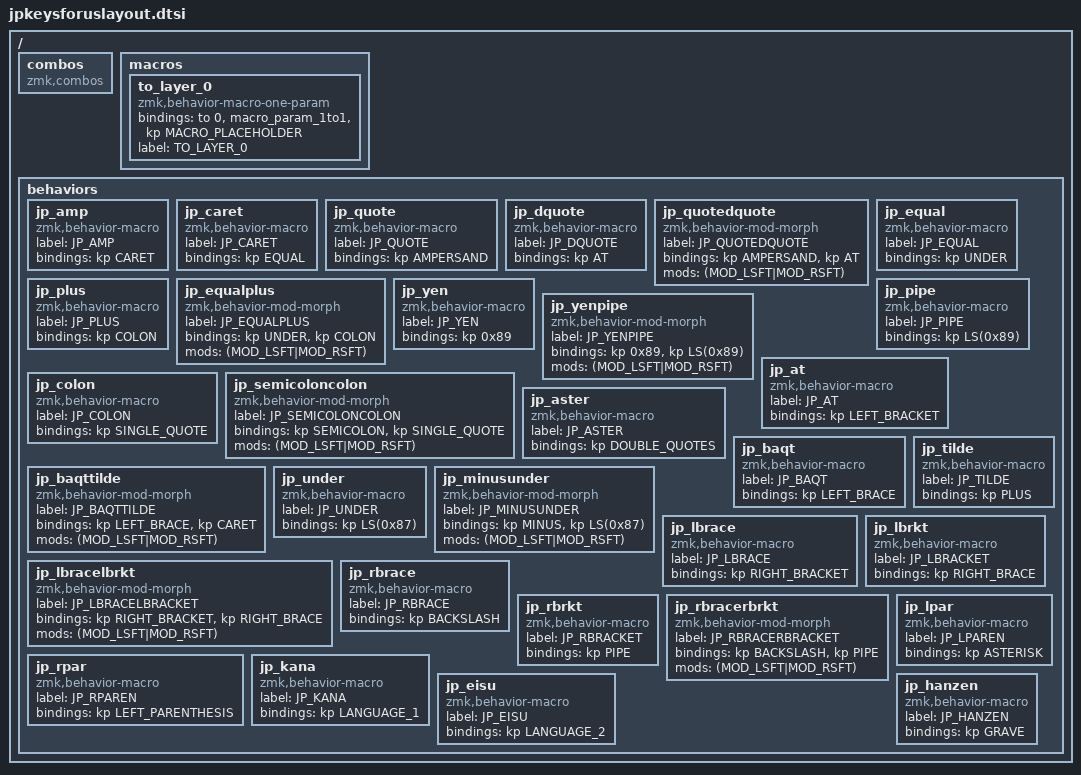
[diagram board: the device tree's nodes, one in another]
/*
 * Copyright (c) 2020 The ZMK Contributors
 *
 * SPDX-License-Identifier: MIT
 */

#include <behaviors.dtsi>
#include <dt-bindings/zmk/keys.h>

/ {
    combos { compatible = "zmk,combos"; };

    macros {
        to_layer_0: to_layer_0 {
            compatible = "zmk,behavior-macro-one-param";
            #binding-cells = <1>;
            bindings = <&to 0 &macro_param_1to1 &kp MACRO_PLACEHOLDER>;
            label = "TO_LAYER_0";
        };
    };

    behaviors {
        /* 日本語キーボード用マクロ定義 */

        jp_amp: jp_amp {
            compatible = "zmk,behavior-macro";
            #binding-cells = <0>;
            label = "JP_AMP";
            bindings = <&kp CARET>;
        };

        jp_caret: jp_caret {
            compatible = "zmk,behavior-macro";
            #binding-cells = <0>;
            label = "JP_CARET";
            bindings = <&kp EQUAL>;
        };

        jp_quote: jp_quote {
            compatible = "zmk,behavior-macro";
            #binding-cells = <0>;
            label = "JP_QUOTE";
            bindings = <&kp AMPERSAND>;
        };

        jp_dquote: jp_dquote {
            compatible = "zmk,behavior-macro";
            #binding-cells = <0>;
            label = "JP_DQUOTE";
            bindings = <&kp AT>;
        };

        jp_quotedquote: jp_quotedquote {
            compatible = "zmk,behavior-mod-morph";
            #binding-cells = <0>;
            label = "JP_QUOTEDQUOTE";
            bindings = <&kp AMPERSAND>, <&kp AT>;
            mods = <(MOD_LSFT|MOD_RSFT)>;
        };

        jp_equal: jp_equal {
            compatible = "zmk,behavior-macro";
            #binding-cells = <0>;
            label = "JP_EQUAL";
            bindings = <&kp UNDER>>;
        };

        jp_plus: jp_plus {
            compatible = "zmk,behavior-macro";
            #binding-cells = <0>;
            label = "JP_PLUS";
            bindings = <&kp COLON>;
        };

        jp_equalplus: jp_equalplus {
            compatible = "zmk,behavior-mod-morph";
            #binding-cells = <0>;
            label = "JP_EQUALPLUS";
            bindings = <&kp UNDER>, <&kp COLON>;
            mods = <(MOD_LSFT|MOD_RSFT)>;
        };

        jp_yen: jp_yen {
            compatible = "zmk,behavior-macro";
            #binding-cells = <0>;
            label = "JP_YEN";
            bindings = <&kp 0x89>;
        };

        jp_pipe: jp_pipe {
            compatible = "zmk,behavior-macro";
            #binding-cells = <0>;
            label = "JP_PIPE";
            bindings = <&kp LS(0x89)>;
        };

        jp_yenpipe: jp_yenpipe {
            compatible = "zmk,behavior-mod-morph";
            #binding-cells = <0>;
            label = "JP_YENPIPE";
            bindings = <&kp 0x89>, <&kp LS(0x89)>;
            mods = <(MOD_LSFT|MOD_RSFT)>;
        };

        jp_at: jp_at {
            compatible = "zmk,behavior-macro";
            #binding-cells = <0>;
            label = "JP_AT";
            bindings = <&kp LEFT_BRACKET>;
        };

        jp_colon: jp_colon {
            compatible = "zmk,behavior-macro";
            #binding-cells = <0>;
            label = "JP_COLON";
            bindings = <&kp SINGLE_QUOTE>;
        };

        jp_semicoloncolon: jp_semicoloncolon {
            compatible = "zmk,behavior-mod-morph";
            #binding-cells = <0>;
            label = "JP_SEMICOLONCOLON";
            bindings = <&kp SEMICOLON>,<&kp SINGLE_QUOTE>;
            mods = <(MOD_LSFT|MOD_RSFT)>;
        };

        jp_aster: jp_aster {
            compatible = "zmk,behavior-macro";
            #binding-cells = <0>;
            label = "JP_ASTER";
            bindings = <&kp DOUBLE_QUOTES>;
        };

        jp_baqt: jp_baqt {
            compatible = "zmk,behavior-macro";
            #binding-cells = <0>;
            label = "JP_BAQT";
            bindings = <&kp LEFT_BRACE>;
        };

        jp_tilde: jp_tilde {
            compatible = "zmk,behavior-macro";
            #binding-cells = <0>;
            label = "JP_TILDE";
            bindings = <&kp PLUS>;
        };

        jp_baqttilde: jp_baqttilde {
            compatible = "zmk,behavior-mod-morph";
            #binding-cells = <0>;
            label = "JP_BAQTTILDE";
            bindings = <&kp LEFT_BRACE>, <&kp CARET>;
            mods = <(MOD_LSFT|MOD_RSFT)>;
        };

        jp_under: jp_under {
            compatible = "zmk,behavior-macro";
            #binding-cells = <0>;
            label = "JP_UNDER";
            bindings = <&kp LS(0x87)>;
        };

        jp_minusunder: jp_minusunder {
            compatible = "zmk,behavior-mod-morph";
            #binding-cells = <0>;
            label = "JP_MINUSUNDER";
            bindings = <&kp MINUS>,<&kp LS(0x87)>;
            mods = <(MOD_LSFT|MOD_RSFT)>;
        };

        jp_lbrace: jp_lbrace {
            compatible = "zmk,behavior-macro";
            #binding-cells = <0>;
            label = "JP_LBRACE";
            bindings = <&kp RIGHT_BRACKET>;
        };

        jp_lbrkt: jp_lbrkt {
            compatible = "zmk,behavior-macro";
            #binding-cells = <0>;
            label = "JP_LBRACKET";
            bindings = <&kp RIGHT_BRACE>;
        };

        jp_lbracelbrkt: jp_lbracelbrkt {
            compatible = "zmk,behavior-mod-morph";
            #binding-cells = <0>;
            label = "JP_LBRACELBRACKET";
            bindings = <&kp RIGHT_BRACKET>,<&kp RIGHT_BRACE>;
            mods = <(MOD_LSFT|MOD_RSFT)>;
        };

        jp_rbrace: jp_rbrace {
            compatible = "zmk,behavior-macro";
            #binding-cells = <0>;
            label = "JP_RBRACE";
            bindings = <&kp BACKSLASH>;
        };

        jp_rbrkt: jp_rbrkt {
            compatible = "zmk,behavior-macro";
            #binding-cells = <0>;
            label = "JP_RBRACKET";
            bindings = <&kp PIPE>;
        };

        jp_rbracerbrkt: jp_rbracerbrkt {
            compatible = "zmk,behavior-mod-morph";
            #binding-cells = <0>;
            label = "JP_RBRACERBRACKET";
            bindings = <&kp BACKSLASH>,<&kp PIPE>;
            mods = <(MOD_LSFT|MOD_RSFT)>;
        };

        jp_lpar: jp_lpar {
            compatible = "zmk,behavior-macro";
            #binding-cells = <0>;
            label = "JP_LPAREN";
            bindings = <&kp ASTERISK>;
        };

        jp_rpar: jp_rpar {
            compatible = "zmk,behavior-macro";
            #binding-cells = <0>;
            label = "JP_RPAREN";
            bindings = <&kp LEFT_PARENTHESIS>;
        };

        jp_kana: jp_kana {
            compatible = "zmk,behavior-macro";
            #binding-cells = <0>;
            label = "JP_KANA";
            bindings = <&kp LANGUAGE_1>;
        };

        jp_eisu: jp_eisu {
            compatible = "zmk,behavior-macro";
            #binding-cells = <0>;
            label = "JP_EISU";
            bindings = <&kp LANGUAGE_2>;
        };

        jp_hanzen: jp_hanzen {
            compatible = "zmk,behavior-macro";
            #binding-cells = <0>;
            label = "JP_HANZEN";
            bindings = <&kp GRAVE>;
        };
    };

};
